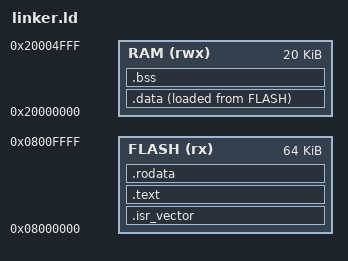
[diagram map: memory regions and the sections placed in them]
ENTRY(Reset_Handler)

MEMORY {
  FLASH (rx)  : ORIGIN = 0x08000000, LENGTH = 64K
  RAM   (rwx) : ORIGIN = 0x20000000, LENGTH = 20K
}
_estack = 0x20005000;

SECTIONS {
  .isr_vector : {
    . = ALIGN(4);
    KEEP(*(.isr_vector))
    . = ALIGN(4);
  } > FLASH

  .text : { *(.text*) } > FLASH
  .rodata : { *(.rodata*) } > FLASH

  _sidata = LOADADDR(.data);
  .data : {
    . = ALIGN(4);
    _sdata = .;
    *(.data*)
    _edata = .;
  } > RAM AT > FLASH

  .bss : {
    . = ALIGN(4);
    _sbss = .;
    *(.bss*)
    *(COMMON)
    _ebss = .;
  } > RAM
}
